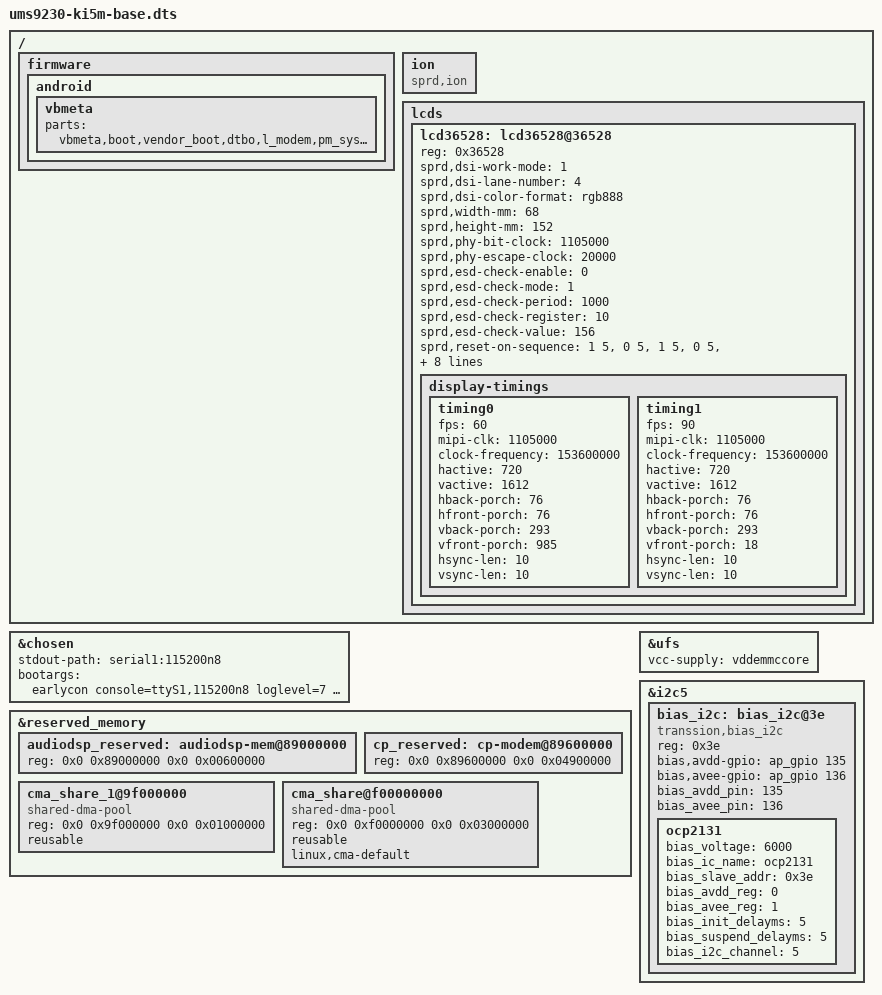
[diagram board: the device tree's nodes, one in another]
// SPDX-License-Identifier: (GPL-2.0+ OR MIT)
#include "ums9230-base.dts"

/ {
	firmware {
		android {
			vbmeta {
				parts = "vbmeta,boot,vendor_boot,dtbo,l_modem,pm_sys,l_ldsp,l_gdsp,l_agdsp";
			};
		};
	};
};

&chosen {
	stdout-path = "serial1:115200n8";
	bootargs = "earlycon console=ttyS1,115200n8 loglevel=7 lcd_name=lcd36528@36528 firmware_class.path=/odm/firmware,/vendor/firmware";
};

&reserved_memory {
	/delete-node/ audiodsp-mem@88f00000;
	/delete-node/ cp-mem@89600000;
	/delete-node/ sysdump-uboot@9f000000;
	/delete-node/ dmabuf,cma;

	audiodsp_reserved: audiodsp-mem@89000000 {
		reg = <0x0 0x89000000 0x0 0x00600000>;
	};

	cp_reserved: cp-modem@89600000 {
		reg = <0x0 0x89600000 0x0 0x04900000>;
	};

	cma_share_1@9f000000 {
		compatible = "shared-dma-pool";
		reg = <0x0 0x9f000000 0x0 0x01000000>;
		reusable;
	};

	cma_share@f00000000 {
		compatible = "shared-dma-pool";
		reg = <0x0 0xf0000000 0x0 0x03000000>;
		reusable;
		linux,cma-default;
	};
};

/* Slot A uses UFS. Keep the donor's 5.15 clock and reset specifiers. */
&ufs {
	vcc-supply = <&vddemmccore>;
	status = "okay";
};

/* KI5m board display data, reconstructed from stock V218 DTB (TASK 0J). */
&i2c5 {
	bias_i2c: bias_i2c@3e {
		compatible = "transsion,bias_i2c";
		reg = <0x3e>;
		status = "okay";

		bias,avdd-gpio = <&ap_gpio 135 0>;
		bias,avee-gpio = <&ap_gpio 136 0>;
		bias_avdd_pin = <135>;
		bias_avee_pin = <136>;

		ocp2131 {
			bias_voltage = <6000>;
			bias_ic_name = "ocp2131";
			bias_slave_addr = <0x3e>;
			bias_avdd_reg = <0>;
			bias_avee_reg = <1>;
			bias_init_delayms = <5>;
			bias_suspend_delayms = <5>;
			bias_i2c_channel = <5>;
		};
	};
};

/ {
	ion: ion {
		compatible = "sprd,ion";
		#address-cells = <1>;
		#size-cells = <0>;
	};

	lcds {
		#address-cells = <1>;
		#size-cells = <0>;

		lcd36528: lcd36528@36528 {
			reg = <0x36528>;
			sprd,dsi-work-mode = <1>;
			sprd,dsi-lane-number = <4>;
			sprd,dsi-color-format = "rgb888";
			sprd,width-mm = <68>;
			sprd,height-mm = <152>;
			sprd,phy-bit-clock = <1105000>;
			sprd,phy-escape-clock = <20000>;
			sprd,esd-check-enable = <0>;
			sprd,esd-check-mode = <1>;
			sprd,esd-check-period = <1000>;
			sprd,esd-check-register = <10>;
			sprd,esd-check-value = <156>;
			sprd,reset-on-sequence = <1 5> <0 5> <1 5> <0 5> <1 10>;
			sprd,reset-off-sequence = <1 1>;
			sprd,sleep-in-command = [13 14 00 01 28 13 78 00 01 10];
			sprd,sleep-out-command = [13 78 00 01 11 13 14 00 01 29];
			sprd,initial-command = [
					23 00 00 02 ff 20 23 00 00 02 fb 01 23 00 00 02
					07 b4 23 00 00 02 08 b4 23 00 00 02 0d 80 23 00
					00 02 1f 22 23 00 00 02 82 66 23 00 00 02 94 c0
					23 00 00 02 95 13 23 00 00 02 96 13 23 00 00 02
					ff 24 23 00 00 02 fb 01 23 00 00 02 01 22 23 00
					00 02 02 21 23 00 00 02 03 26 23 00 00 02 04 04
					23 00 00 02 05 05 23 00 00 02 06 0c 23 00 00 02
					07 0d 23 00 00 02 08 0e 23 00 00 02 09 0f 23 00
					00 02 0a 10 23 00 00 02 0b 11 23 00 00 02 0c 12
					23 00 00 02 0d 13 23 00 00 02 0e 23 23 00 00 02
					0f 20 23 00 00 02 17 24 23 00 00 02 18 21 23 00
					00 02 19 26 23 00 00 02 1a 04 23 00 00 02 1b 05
					23 00 00 02 1c 0c 23 00 00 02 1d 0d 23 00 00 02
					1e 0e 23 00 00 02 1f 0f 23 00 00 02 20 10 23 00
					00 02 21 11 23 00 00 02 22 12 23 00 00 02 23 13
					23 00 00 02 24 25 23 00 00 02 25 20 23 00 00 02
					2f 13 23 00 00 02 30 0f 23 00 00 02 33 0f 23 00
					00 02 34 13 23 00 00 02 37 88 23 00 00 02 3a 06
					23 00 00 02 3b c8 23 00 00 02 3d 62 23 00 00 02
					50 87 23 00 00 02 51 56 23 00 00 02 52 34 23 00
					00 02 53 12 23 00 00 02 54 78 39 00 00 03 55 4e
					0e 23 00 00 02 56 08 23 00 00 02 5c 8a 23 00 00
					02 5d 0a 39 00 00 03 5e 00 08 23 00 00 02 af 14
					23 00 00 02 b0 09 23 00 00 02 b1 14 23 00 00 02
					b2 09 23 00 00 02 c5 03 23 00 00 02 c7 14 23 00
					00 02 c8 09 23 00 00 02 c9 14 23 00 00 02 ca 09
					23 00 00 02 ff 25 23 00 00 02 fb 01 23 00 00 02
					44 06 23 00 00 02 5d 06 23 00 00 02 5e c8 23 00
					00 02 c0 8c 23 00 00 02 c6 10 23 00 00 02 ff 26
					23 00 00 02 fb 01 23 00 00 02 4d 06 23 00 00 02
					4e 78 23 00 00 02 6e 06 23 00 00 02 6f 78 23 00
					00 02 7b 06 23 00 00 02 7c 78 23 00 00 02 ff 27
					23 00 00 02 fb 01 23 00 00 02 14 66 23 00 00 02
					15 d8 23 00 00 02 1a 66 23 00 00 02 1b 66 23 00
					00 02 78 98 23 00 00 02 79 0f 23 00 00 02 7a 0f
					23 00 00 02 7c 0a 23 00 00 02 7d 69 23 00 00 02
					7e 0a 23 00 00 02 7f 69 23 00 00 02 80 0a 23 00
					00 02 81 69 23 00 00 02 83 14 23 00 00 02 84 10
					23 00 00 02 87 10 23 00 00 02 88 14 23 00 00 02
					93 80 23 00 00 02 94 80 23 00 00 02 96 0b 23 00
					00 02 97 15 23 00 00 02 98 88 23 00 00 02 c4 06
					23 00 00 02 c5 78 23 00 00 02 c6 06 23 00 00 02
					c7 78 23 00 00 02 e4 00 23 00 00 02 e5 9d 23 00
					00 02 ff 2a 23 00 00 02 fb 01 23 00 00 02 64 16
					23 00 00 02 67 16 23 00 00 02 6a 16 23 00 00 02
					73 1e 23 00 00 02 76 1e 23 00 00 02 79 16 23 00
					00 02 7c 16 23 00 00 02 7f 16 23 00 00 02 82 16
					23 00 00 02 85 16 23 00 00 02 a2 3f 23 00 00 02
					a3 ff 23 00 00 02 a4 c3 23 00 00 02 ff 24 23 00
					00 02 fb 01 23 00 00 02 59 70 23 00 00 02 5a bc
					23 00 00 02 5b aa 23 00 00 02 61 4c 23 00 00 02
					92 ce 39 00 00 03 93 12 00 23 00 00 02 94 c8 23
					00 00 02 dc c9 23 00 00 02 e0 c9 23 00 00 02 e2
					c9 23 00 00 02 e4 c9 23 00 00 02 e6 c9 23 00 00
					02 ea c9 23 00 00 02 ee c9 23 00 00 02 f0 c9 23
					00 00 02 ff 25 23 00 00 02 fb 01 23 00 00 02 13
					02 23 00 00 02 14 72 23 00 00 02 15 01 23 00 00
					02 16 8b 23 00 00 02 1f bc 23 00 00 02 20 aa 23
					00 00 02 26 bc 23 00 00 02 27 aa 23 00 00 02 48
					bc 23 00 00 02 49 aa 23 00 00 02 50 bc 23 00 00
					02 51 aa 23 00 00 02 61 bc 23 00 00 02 62 aa 23
					00 00 02 68 08 23 00 00 02 bc 24 23 00 00 02 ff
					26 23 00 00 02 fb 01 23 00 00 02 00 80 23 00 00
					02 02 0d 23 00 00 02 04 2f 23 00 00 02 09 05 23
					00 00 02 0a 05 23 00 00 02 19 0b 23 00 00 02 1a
					54 23 00 00 02 1b 0a 23 00 00 02 1c c9 23 00 00
					02 1e ce 23 00 00 02 1f ce 23 00 00 02 24 00 23
					00 00 02 25 ce 23 00 00 02 2a 0b 23 00 00 02 2b
					54 23 00 00 02 2f 05 23 00 00 02 30 ce 23 00 00
					02 32 ce 23 00 00 02 37 11 23 00 00 02 38 01 23
					00 00 02 39 08 23 00 00 02 3a ce 23 00 00 02 40
					81 23 00 00 02 41 81 23 00 00 02 42 81 23 00 00
					02 44 81 23 00 00 02 46 81 23 00 00 02 48 81 23
					00 00 02 49 08 23 00 00 02 4a 81 23 00 00 02 51
					7b 23 00 00 02 52 69 23 00 00 02 56 7b 23 00 00
					02 58 69 23 00 00 02 5b 7b 23 00 00 02 5c 69 23
					00 00 02 60 7b 23 00 00 02 61 69 23 00 00 02 64
					7b 23 00 00 02 65 69 23 00 00 02 69 7b 23 00 00
					02 6a 69 23 00 00 02 72 7b 23 00 00 02 73 69 23
					00 00 02 8b 35 23 00 00 02 8c 09 23 00 00 02 8d
					00 23 00 00 02 99 0b 23 00 00 02 9a 54 23 00 00
					02 9b 0a 23 00 00 02 9c c9 23 00 00 02 9d 0b 23
					00 00 02 9e 54 23 00 00 02 c3 00 23 00 00 02 ff
					27 23 00 00 02 fb 01 23 00 00 02 58 a4 39 00 00
					03 59 00 12 39 00 00 03 5a 00 c3 39 00 00 03 5d
					00 01 39 00 00 03 5e 00 b1 23 00 00 02 5f 01 39
					00 00 03 60 06 75 23 00 00 02 c0 08 23 00 00 02
					f0 77 23 00 00 02 f1 10 23 00 00 02 f4 00 23 00
					00 02 f5 77 23 00 00 02 ff 2a 23 00 00 02 fb 01
					23 00 00 02 04 7c 23 00 00 02 06 7c 23 00 00 02
					09 7c 23 00 00 02 0b 7c 23 00 00 02 0d 7c 23 00
					00 02 14 7c 23 00 00 02 15 7c 23 00 00 02 16 7c
					23 00 00 02 23 0c 23 00 00 02 28 12 23 00 00 02
					2d 12 23 00 00 02 33 12 23 00 00 02 35 0a 23 00
					00 02 37 79 23 00 00 02 99 95 23 00 00 02 9a 0b
					23 00 00 02 c4 80 23 00 00 02 c5 12 23 00 00 02
					c6 01 23 00 00 02 c7 2a 23 00 00 02 c8 10 23 00
					00 02 c9 01 23 00 00 02 ca 18 23 00 00 02 cb 16
					23 00 00 02 cc 75 23 00 00 02 ff 23 23 00 00 02
					fb 01 23 00 00 02 00 80 23 00 00 02 07 00 23 00
					00 02 08 01 23 00 00 02 09 01 23 00 00 02 11 00
					23 00 00 02 12 b5 23 00 00 02 15 e7 23 00 00 02
					16 14 23 00 00 02 ff 25 23 00 00 02 fb 01 39 00
					00 05 02 00 00 00 40 23 00 00 02 ff 2a 23 00 00
					02 fb 01 23 00 00 02 99 95 23 00 00 02 9a 0b 23
					00 00 02 ac 00 23 00 00 02 ad 3c 23 00 00 02 ae
					80 23 00 00 02 af 43 23 00 00 02 b0 18 23 00 00
					02 b1 90 23 00 00 02 b3 22 23 00 00 02 ff 26 23
					00 00 02 fb 01 23 00 00 02 45 05 23 00 00 02 cb
					00 23 00 00 02 d6 00 23 00 00 02 d7 00 23 00 00
					02 d8 00 23 00 00 02 d9 00 23 00 00 02 da 00 23
					00 00 02 db 00 23 00 00 02 dc 00 23 00 00 02 dd
					00 23 00 00 02 ff 25 23 00 00 02 fb 01 23 00 00
					02 bc 24 23 00 00 02 ff 26 23 00 00 02 fb 01 23
					00 00 02 09 05 23 00 00 02 ff 2a 23 00 00 02 fb
					01 23 00 00 02 23 0c 23 00 00 02 ff 20 23 00 00
					02 fb 01 23 00 00 02 07 b4 23 00 00 02 ff 10 23
					00 00 02 fb 01 23 00 00 02 53 2c 23 00 00 02 55
					03 39 00 00 03 51 00 00 39 00 00 03 68 03 01 23
					00 00 02 ba 03 13 78 00 01 11 13 14 00 01 29
			];

			display-timings {
				timing0 {
					fps = <60>;
					mipi-clk = <1105000>;
					clock-frequency = <153600000>;
					hactive = <720>;
					vactive = <1612>;
					hback-porch = <76>;
					hfront-porch = <76>;
					vback-porch = <293>;
					vfront-porch = <985>;
					hsync-len = <10>;
					vsync-len = <10>;
				};
				timing1 {
					fps = <90>;
					mipi-clk = <1105000>;
					clock-frequency = <153600000>;
					hactive = <720>;
					vactive = <1612>;
					hback-porch = <76>;
					hfront-porch = <76>;
					vback-porch = <293>;
					vfront-porch = <18>;
					hsync-len = <10>;
					vsync-len = <10>;
				};
			};
		};
	};
};
